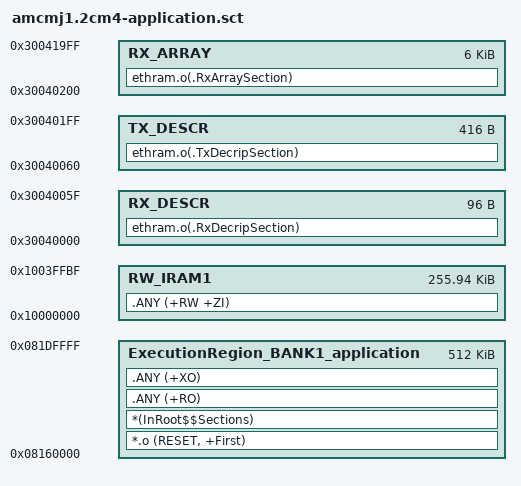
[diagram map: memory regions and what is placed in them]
; amcmj1-application running on cm4. it uses following FLASH and RAM resources:
; 
; - FLASH: 1st bank @ 0x08160000 for a size of 512k
; 
; - RAM: RAM: SRAM1-SRAM2 @ 0x10000000 for a size of 256K - 64
; 
; the memory for IPC is @ 0x1003FFC0, on the top 64 bytes of SRAM1-SRAM2 used by the CM4

LoadRegion_BANK1_application 0x08160000 0x00080000  {

  ; execution region is in flash
  ExecutionRegion_BANK1_application 0x08160000 0x00080000  {  ; load address = execution address
   *.o (RESET, +First)
   *(InRoot$$Sections)
   .ANY (+RO)
   .ANY (+XO)
  }
  
  RX_DESCR	0x30040000 0x00000060 {
  	ethram.o(.RxDecripSection)
  }
  TX_DESCR	0x30040060 0x000001A0 {
  	ethram.o(.TxDecripSection)
  }
  RX_ARRAY 	0x30040200 0x00001800 {
  	ethram.o(.RxArraySection)
  }
  
  ; banks sram1 and sram2 joined together with a 64 bytes hole on top for ipc
  RW_IRAM1 0x10000000 0x0003FFC0 {
   .ANY (+RW +ZI)
  }
  
  
}





